AUTOSAR XML (schema 3.1.2)
package /Components/SWC_ThrSpT
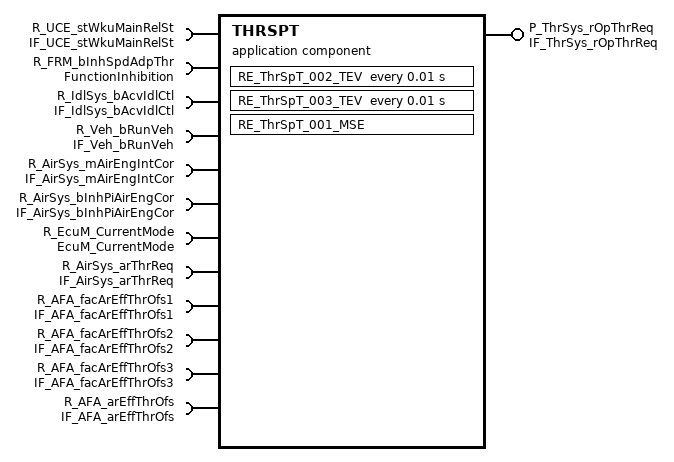
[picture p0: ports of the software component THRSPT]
  application software component type THRSPT  # ThrSpT
    require port R_UCE_stWkuMainRelSt: required-interface=IF_UCE_stWkuMainRelSt
    require port R_FRM_bInhSpdAdpThr: required-interface=FunctionInhibition
    provide port P_ThrSys_rOpThrReq: unqueued-sender-com-spec{data-element=ThrSys_rOpThrReq, can-invalidate=false, init-value=UInt16InitValue}, provided-interface=IF_ThrSys_rOpThrReq
    10 x require port:
      R_IdlSys_bAcvIdlCtl: unqueued-receiver-com-spec{data-element=IdlSys_bAcvIdlCtl, init-value=ConstantValue, resync-time=0}, required-interface=IF_IdlSys_bAcvIdlCtl
      R_Veh_bRunVeh: unqueued-receiver-com-spec{data-element=Veh_bRunVeh, init-value=BooleanInitValue, resync-time=0}, required-interface=IF_Veh_bRunVeh
      R_AirSys_mAirEngIntCor: unqueued-receiver-com-spec{data-element=AirSys_mAirEngIntCor, init-value=ConstantValue1, resync-time=0}, required-interface=IF_AirSys_mAirEngIntCor
      R_AirSys_bInhPiAirEngCor: unqueued-receiver-com-spec{data-element=AirSys_bInhPiAirEngCor, init-value=ConstantValue3, resync-time=0}, required-interface=IF_AirSys_bInhPiAirEngCor
      R_EcuM_CurrentMode: required-interface=EcuM_CurrentMode
      R_AirSys_arThrReq: unqueued-receiver-com-spec{data-element=AirSys_arThrReq, init-value=ConstantValue5, resync-time=0}, required-interface=IF_AirSys_arThrReq
      R_AFA_facArEffThrOfs1: unqueued-receiver-com-spec{data-element=AFA_facArEffThrOfs1, init-value=ConstantValue7, resync-time=0}, required-interface=IF_AFA_facArEffThrOfs1
      R_AFA_facArEffThrOfs2: unqueued-receiver-com-spec{data-element=AFA_facArEffThrOfs2, init-value=ConstantValue9, resync-time=0}, required-interface=IF_AFA_facArEffThrOfs2
      R_AFA_facArEffThrOfs3: unqueued-receiver-com-spec{data-element=AFA_facArEffThrOfs3, init-value=ConstantValue11, resync-time=0}, required-interface=IF_AFA_facArEffThrOfs3
      R_AFA_arEffThrOfs: unqueued-receiver-com-spec{data-element=AFA_arEffThrOfs, init-value=ConstantValue13, resync-time=0}, required-interface=IF_AFA_arEffThrOfs
  11 x constant specification:
    BooleanInitValue
      value:
        boolean literal BooleanInitValue: type=DT_Veh_bRunVeh, value=false
    ConstantValue
      value:
        boolean literal ConstantValue: type=DT_IdlSys_bAcvIdlCtl, value=false
    ConstantValue1
      value:
        integer literal ConstantValue1: type=DT_AirSys_mAirEngIntCor, value=2147456160
    ConstantValue11
      value:
        integer literal ConstantValue11: type=DT_AFA_facArEffThrOfs3, value=0
    ConstantValue13
      value:
        integer literal ConstantValue13: type=DT_AFA_arEffThrOfs, value=0
    ConstantValue3
      value:
        boolean literal ConstantValue3: type=DT_AirSys_bInhPiAirEngCor, value=false
    ConstantValue5
      value:
        integer literal ConstantValue5: type=DT_AirSys_arThrReq, value=0
    ConstantValue7
      value:
        integer literal ConstantValue7: type=DT_AFA_facArEffThrOfs1, value=0
    ConstantValue9
      value:
        integer literal ConstantValue9: type=DT_AFA_facArEffThrOfs2, value=0
    InitValue_SInt32_0
      value:
        integer literal InitValue_SInt32_0: type=DT_ThrSys_arSpdAdpThr_irv, value=0
    UInt16InitValue
      value:
        integer literal UInt16InitValue: type=DT_ThrSys_rOpThrReq, value=0
  internal behavior IB_ThrSpT: component=THRSPT
    mode switch event EV_ThrSpT_001_MSE: start-on-event=RE_ThrSpT_001_MSE, activation=ENTRY, mode=R_EcuM_CurrentMode.currentMode.RUN
    timing event EV_ThrSpT_002_TEV: mode-dependency=dependent-on-mode=[R_UCE_stWkuMainRelSt.RCD_stWkuMainRelSt.PreMainWakeUp, R_UCE_stWkuMainRelSt.RCD_stWkuMainRelSt.PostMainWakeUp, R_UCE_stWkuMainRelSt.RCD_stWkuMainRelSt.Invalid], start-on-event=RE_ThrSpT_002_TEV, period=0.01
    timing event EV_ThrSpT_003_TEV: mode-dependency=dependent-on-mode=[R_UCE_stWkuMainRelSt.RCD_stWkuMainRelSt.PreMainWakeUp, R_UCE_stWkuMainRelSt.RCD_stWkuMainRelSt.PostMainWakeUp, R_UCE_stWkuMainRelSt.RCD_stWkuMainRelSt.Invalid], start-on-event=RE_ThrSpT_003_TEV, period=0.01
    inter runnable variable ThrSys_arSpdAdpThr_irv: sw-calibration-access=READ-WRITE, type=DT_ThrSys_arSpdAdpThr_irv, communication-approach=EXPLICIT, init-value=InitValue_SInt32_0
    runnable RE_ThrSpT_001_MSE: written-variable=ThrSys_arSpdAdpThr_irv
      data send point ds_ThrSys_rOpThrReq: data-element=P_ThrSys_rOpThrReq.ThrSys_rOpThrReq
    runnable RE_ThrSpT_003_TEV: read-variable=ThrSys_arSpdAdpThr_irv, written-variable=ThrSys_arSpdAdpThr_irv
      4 x data receive point:
        dr_Veh_bRunVeh: data-element=R_Veh_bRunVeh.Veh_bRunVeh
        dr_AirSys_bInhPiAirEngCor: data-element=R_AirSys_bInhPiAirEngCor.AirSys_bInhPiAirEngCor
        dr_IdlSys_bAcvIdlCtl: data-element=R_IdlSys_bAcvIdlCtl.IdlSys_bAcvIdlCtl
        dr_AirSys_mAirEngIntCor: data-element=R_AirSys_mAirEngIntCor.AirSys_mAirEngIntCor
      sync call ssp_FRM_bInhSpdAdpThr: operation=R_FRM_bInhSpdAdpThr.GetFunctionPermission
    runnable RE_ThrSpT_002_TEV: read-variable=ThrSys_arSpdAdpThr_irv
      5 x data receive point:
        dr_AFA_facArEffThrOfs2: data-element=R_AFA_facArEffThrOfs2.AFA_facArEffThrOfs2
        dr_AFA_facArEffThrOfs1: data-element=R_AFA_facArEffThrOfs1.AFA_facArEffThrOfs1
        dr_AFA_facArEffThrOfs3: data-element=R_AFA_facArEffThrOfs3.AFA_facArEffThrOfs3
        dr_AFA_arEffThrOfs: data-element=R_AFA_arEffThrOfs.AFA_arEffThrOfs
        dr_AirSys_arThrReq: data-element=R_AirSys_arThrReq.AirSys_arThrReq
      data send point ds_ThrSys_rOpThrReq: data-element=P_ThrSys_rOpThrReq.ThrSys_rOpThrReq
  swc implementation Imp_ThrSpT: code-generator=Real-Time Workshop Embedded Coder 5.5 (R2010a) 25-Jan-2010, programming-language=C, behavior=IB_ThrSpT
    code-descriptors:
      code CodeDescriptor: type=SRC
        11 x xfile:
          ThrSpT_Version_h: url=ThrSpT_Version.h
          ThrSpT_h: url=ThrSpT.h
          ThrSpT_nvm_c: url=ThrSpT_nvm.c
          ThrSpT_Version_c: url=ThrSpT_Version.c
          ThrSpT_types_h: url=ThrSpT_types.h
          ThrSpT_private_h: url=ThrSpT_private.h
          ThrSpT_nvm_h: url=ThrSpT_nvm.h
          ThrSpT_import_h: url=ThrSpT_import.h
          ThrSpT_MemMap_h: url=ThrSpT_MemMap.h
          ThrSpT_Def_c: url=ThrSpT_Def.c
          ThrSpT_c: url=ThrSpT.c
package /Components/SWC_ThrSpT/ThrSpT_IRVDatatypes
  integer type DT_ThrSys_arSpdAdpThr_irv: base-type=int32, lower-limit=-2147483648, upper-limit=2147483647
